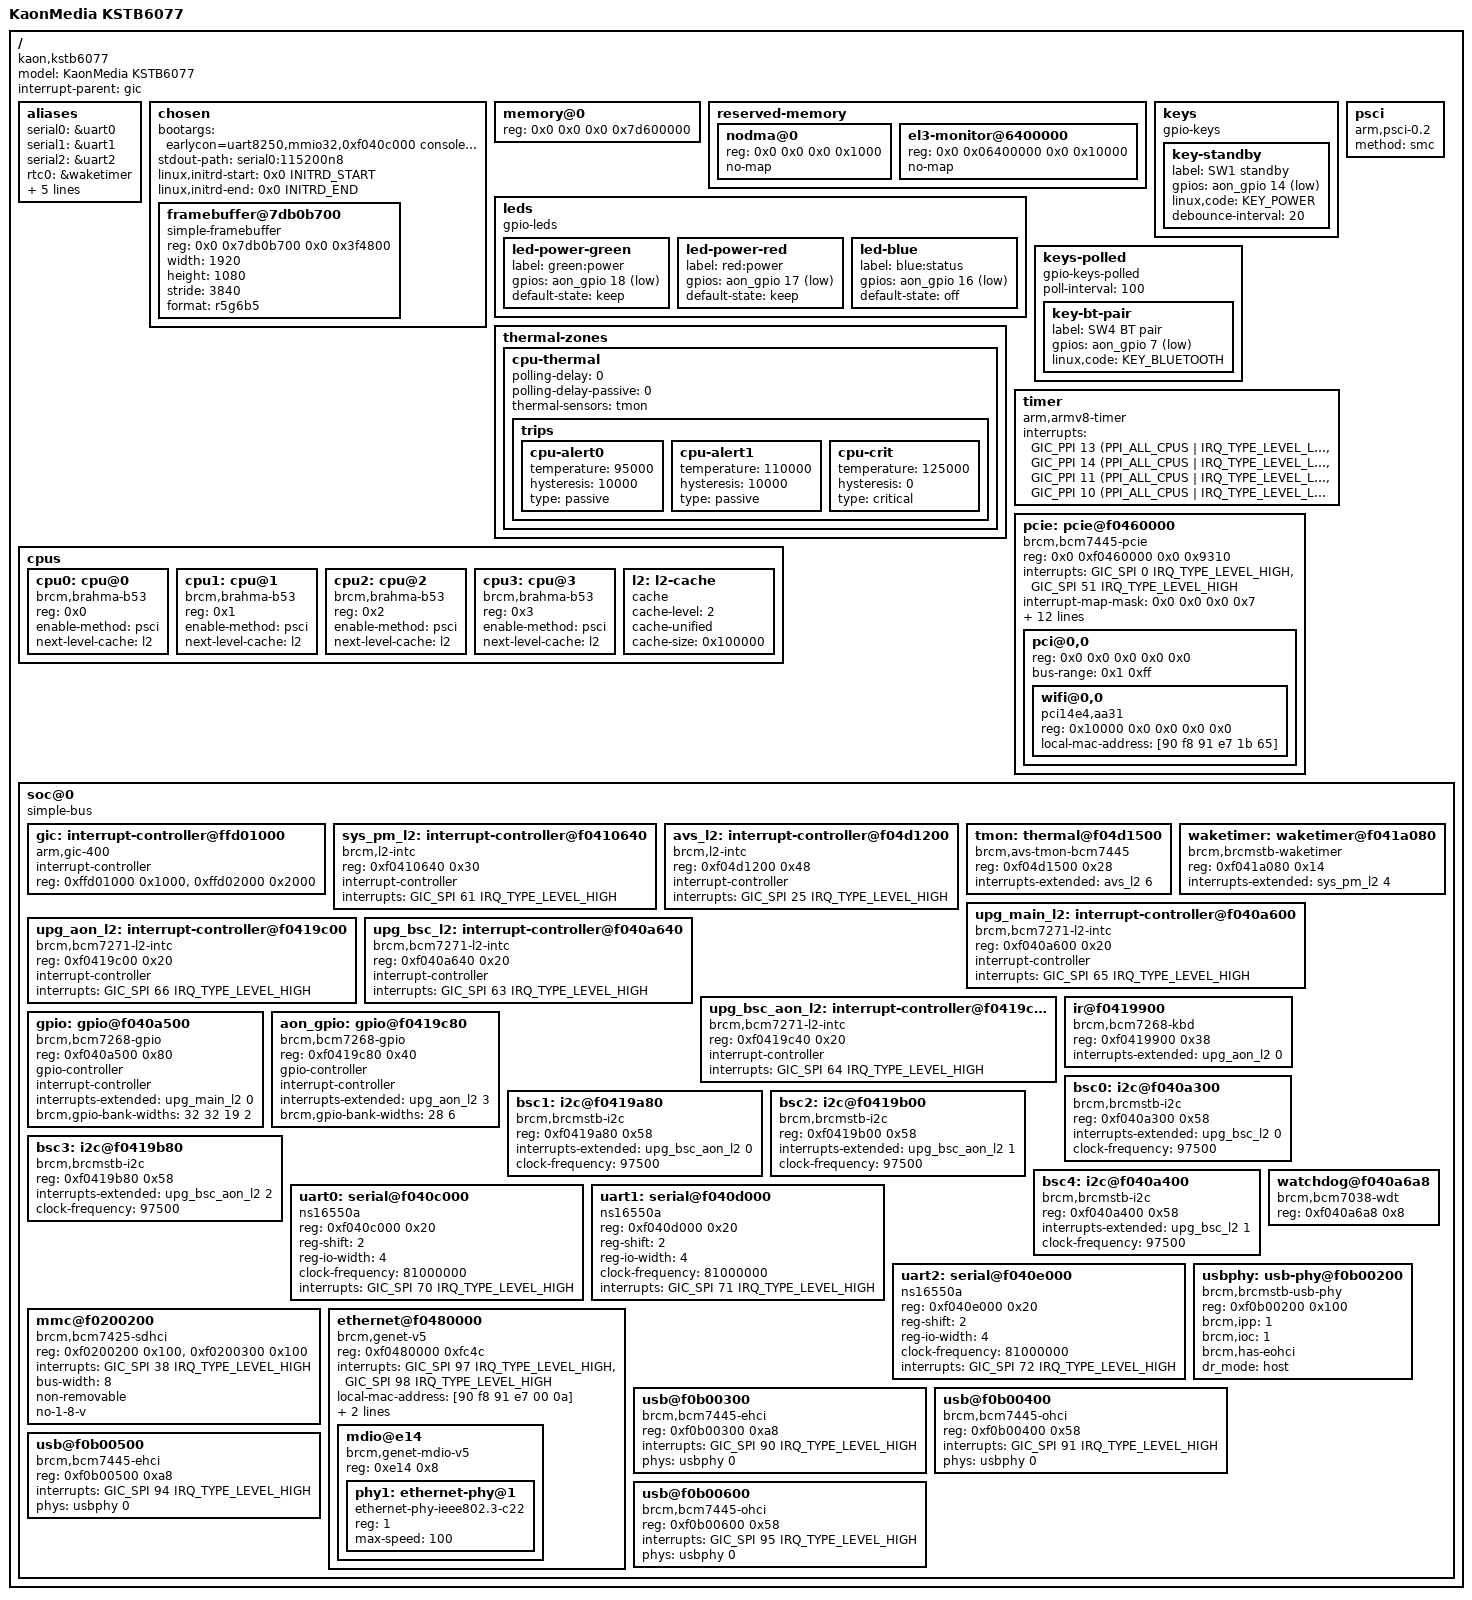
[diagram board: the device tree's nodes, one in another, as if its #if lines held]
// kstb6077.dts - device tree for arm64 Linux on the KSTB6077 (BCM7268 B0).
//
// Written by hand from the tested chapters in docs/ (no BCM7268 tree exists
// upstream). Only what has been checked is described; more nodes are added
// as each driver is tried. INITRD_START/INITRD_END come from the Makefile.

/dts-v1/;

#define GIC_SPI 0
#define GIC_PPI 1
#define IRQ_TYPE_LEVEL_HIGH 4
#define IRQ_TYPE_LEVEL_LOW 8
#define IRQ_TYPE_EDGE_BOTH 3
#define PPI_ALL_CPUS (0xf << 8)
#define GPIO_ACTIVE_LOW 1
#define GPIO_OPEN_DRAIN 6
#define EV_KEY 1
#define KEY_POWER 116
#define KEY_BLUETOOTH 237

/ {
	model = "KaonMedia KSTB6077";
	compatible = "kaon,kstb6077", "brcm,bcm7268";
	#address-cells = <2>;
	#size-cells = <2>;
	interrupt-parent = <&gic>;

	aliases {
		serial0 = &uart0;
		serial1 = &uart1;
		serial2 = &uart2;
		rtc0 = &waketimer;
		i2c0 = &bsc0;
		i2c1 = &bsc1;
		i2c2 = &bsc2;
		i2c3 = &bsc3;
		i2c4 = &bsc4;
	};

	chosen {
		#address-cells = <2>;
		#size-cells = <2>;
		ranges;
		// earlycon without a baud rate: it keeps BOLT's divisor (44, 115200).
		// ROOTFS: root on ROOT (mmcblk0p8), read-only until kstb-rc has checked
		// it with fsck; else the initramfs
#ifdef ROOTFS
		bootargs = "earlycon=uart8250,mmio32,0xf040c000 console=tty0 console=ttyS0,115200 root=/dev/mmcblk0p8 rootfstype=ext4 rootwait ro";
#else
		bootargs = "earlycon=uart8250,mmio32,0xf040c000 console=tty0 console=ttyS0,115200 rdinit=/sbin/init";
#endif
		stdout-path = "serial0:115200n8";
#ifndef ROOTFS
		linux,initrd-start = <0x0 INITRD_START>;
		linux,initrd-end = <0x0 INITRD_END>;
#endif

		// BOLT's splash framebuffer, which kmon keeps on screen at 1080p59.94
		// (docs/hardware/display.md); the display keeps scanning it out
		framebuffer@7db0b700 {
			compatible = "simple-framebuffer";
			reg = <0x0 0x7db0b700 0x0 0x3f4800>;
			width = <1920>;
			height = <1080>;
			stride = <3840>;
			format = "r5g6b5";
		};
	};

	// 2 GB at 0 (docs/hardware/memory-map.md). Linux gets everything below
	// the display and audio buffers at 0x7d600000; above that the display
	// keeps scanning out and the secure regions (BL31, SRR) start at 0x7df00000.
	memory@0 {
		device_type = "memory";
		reg = <0x0 0x0 0x0 0x7d600000>;
	};

	reserved-memory {
		#address-cells = <2>;
		#size-cells = <2>;
		ranges;

		// DTB reserved-nodma
		nodma@0 {
			reg = <0x0 0x0 0x0 0x1000>;
			no-map;
		};

		// kboot's EL3 monitor (or BOLT's smm64): PSCI, cores' EL3 stacks
		el3-monitor@6400000 {
			reg = <0x0 0x06400000 0x0 0x10000>;
			no-map;
		};
	};

	// front LEDs on AON GPIO bank 0 (docs/hardware/gpio.md), open-drain,
	// active-low. BOLT leaves green on; blue is an input until Linux drives it
	leds {
		compatible = "gpio-leds";

		led-power-green {
			label = "green:power";
			gpios = <&aon_gpio 18 (GPIO_ACTIVE_LOW | GPIO_OPEN_DRAIN)>;
			default-state = "keep";
		};

		led-power-red {
			label = "red:power";
			gpios = <&aon_gpio 17 (GPIO_ACTIVE_LOW | GPIO_OPEN_DRAIN)>;
			default-state = "keep";
		};

		led-blue {
			label = "blue:status";
			gpios = <&aon_gpio 16 (GPIO_ACTIVE_LOW | GPIO_OPEN_DRAIN)>;
			default-state = "off";
		};
	};

	// SW1, the front standby button: AON GPIO 14, active-low, interrupt on
	// both edges through the AON L2 (bit 3)
	keys {
		compatible = "gpio-keys";

		key-standby {
			label = "SW1 standby";
			gpios = <&aon_gpio 14 GPIO_ACTIVE_LOW>;
			linux,code = <KEY_POWER>;
			debounce-interval = <20>;
		};
	};

	// SW4, the recovery / Bluetooth-pairing button: AON GPIO 7, active-low;
	// polled, as in the stock DTB
	keys-polled {
		compatible = "gpio-keys-polled";
		poll-interval = <100>;

		key-bt-pair {
			label = "SW4 BT pair";
			gpios = <&aon_gpio 7 GPIO_ACTIVE_LOW>;
			linux,code = <KEY_BLUETOOTH>;
		};
	};

	// AVS temperature monitor; trips as in the stock DTB (95 / 110 / 125 °C,
	// passive, no cooling device yet) plus a critical one, reported by the
	// TMON's interrupt instead of polling
	thermal-zones {
		cpu-thermal {
			polling-delay = <0>;
			polling-delay-passive = <0>;
			thermal-sensors = <&tmon>;

			trips {
				cpu-alert0 {
					temperature = <95000>;
					hysteresis = <10000>;
					type = "passive";
				};

				cpu-alert1 {
					temperature = <110000>;
					hysteresis = <10000>;
					type = "passive";
				};

				cpu-crit {
					temperature = <125000>;
					hysteresis = <0>;
					type = "critical";
				};
			};
		};
	};

	psci {
		compatible = "arm,psci-0.2";
		method = "smc";
	};

	cpus {
		#address-cells = <1>;
		#size-cells = <0>;

		cpu0: cpu@0 {
			device_type = "cpu";
			compatible = "brcm,brahma-b53", "arm,cortex-a53";
			reg = <0x0>;
			enable-method = "psci";
			next-level-cache = <&l2>;
		};

		cpu1: cpu@1 {
			device_type = "cpu";
			compatible = "brcm,brahma-b53", "arm,cortex-a53";
			reg = <0x1>;
			enable-method = "psci";
			next-level-cache = <&l2>;
		};

		cpu2: cpu@2 {
			device_type = "cpu";
			compatible = "brcm,brahma-b53", "arm,cortex-a53";
			reg = <0x2>;
			enable-method = "psci";
			next-level-cache = <&l2>;
		};

		cpu3: cpu@3 {
			device_type = "cpu";
			compatible = "brcm,brahma-b53", "arm,cortex-a53";
			reg = <0x3>;
			enable-method = "psci";
			next-level-cache = <&l2>;
		};

		l2: l2-cache {
			compatible = "cache";
			cache-level = <2>;
			cache-unified;
			cache-size = <0x100000>;
		};
	};

	// IDs 29, 30, 27, 26 (docs/hardware/interrupts.md); CNTFRQ (27 MHz) is
	// set at EL3 by kboot or smm64
	timer {
		compatible = "arm,armv8-timer";
		interrupts = <GIC_PPI 13 (PPI_ALL_CPUS | IRQ_TYPE_LEVEL_LOW)>,
			     <GIC_PPI 14 (PPI_ALL_CPUS | IRQ_TYPE_LEVEL_LOW)>,
			     <GIC_PPI 11 (PPI_ALL_CPUS | IRQ_TYPE_LEVEL_LOW)>,
			     <GIC_PPI 10 (PPI_ALL_CPUS | IRQ_TYPE_LEVEL_LOW)>;
	};

	// PCIe (docs/hardware/peripherals.md): the register layout of the
	// driver's generic STB type (RGR1_SW_INIT_1 +0x9210, MISC_REVISION +0x406c
	// = 0x304). Outbound windows, inbound 2 GB at 0 and the interrupts as in
	// the stock DTB (MSI SPI 51 = ID 83, INTA-INTD SPIs 46-49); one lane, the
	// Wi-Fi chip BCM43570 behind it. The stock DTB's Wi-Fi supplies (AON GPIO
	// 21, 26) are left out: the chip comes up with them as inputs or driven low
	pcie: pcie@f0460000 {
		compatible = "brcm,bcm7445-pcie";
		reg = <0x0 0xf0460000 0x0 0x9310>;
		device_type = "pci";
		#address-cells = <3>;
		#size-cells = <2>;
		#interrupt-cells = <1>;
		interrupts = <GIC_SPI 0 IRQ_TYPE_LEVEL_HIGH>,
			     <GIC_SPI 51 IRQ_TYPE_LEVEL_HIGH>;
		interrupt-names = "pcie", "msi";
		interrupt-map-mask = <0x0 0x0 0x0 0x7>;
		interrupt-map = <0 0 0 1 &gic GIC_SPI 46 IRQ_TYPE_LEVEL_HIGH>,
				<0 0 0 2 &gic GIC_SPI 47 IRQ_TYPE_LEVEL_HIGH>,
				<0 0 0 3 &gic GIC_SPI 48 IRQ_TYPE_LEVEL_HIGH>,
				<0 0 0 4 &gic GIC_SPI 49 IRQ_TYPE_LEVEL_HIGH>;
		msi-controller;
		msi-parent = <&pcie>;
		bus-range = <0x0 0xff>;
		linux,pci-domain = <0>;
		ranges = <0x02000000 0x0 0xc0000000 0x0 0xc0000000 0x0 0x08000000>,
			 <0x02000000 0x0 0xc8000000 0x0 0xc8000000 0x0 0x08000000>,
			 <0x02000000 0x0 0xd0000000 0x0 0xd0000000 0x0 0x08000000>,
			 <0x02000000 0x0 0xd8000000 0x0 0xd8000000 0x0 0x08000000>;
		dma-ranges = <0x43000000 0x0 0x0 0x0 0x0 0x0 0x80000000>;
		brcm,scb-sizes = <0x0 0x80000000>;

		pci@0,0 {
			device_type = "pci";
			reg = <0x0 0x0 0x0 0x0 0x0>;
			bus-range = <0x1 0xff>;
			#address-cells = <3>;
			#size-cells = <2>;
			ranges;

			// the Wi-Fi chip on bus 1 (brcmfmac): the MAC from the stock DTB;
			// its board file is the stock nvm.txt, installed as
			// /lib/firmware/brcm/brcmfmac43570-pcie.kaon,kstb6077.txt
			wifi@0,0 {
				compatible = "pci14e4,aa31", "brcm,bcm4329-fmac";
				reg = <0x10000 0x0 0x0 0x0 0x0>;
				local-mac-address = [90 f8 91 e7 1b 65];
			};
		};
	};

	soc@0 {
		compatible = "simple-bus";
		#address-cells = <1>;
		#size-cells = <1>;
		ranges = <0x0 0x0 0x0 0xffffffff>;

		// GIC-400: distributor and CPU interface
		gic: interrupt-controller@ffd01000 {
			compatible = "arm,gic-400";
			#interrupt-cells = <3>;
			#address-cells = <0>;
			interrupt-controller;
			reg = <0xffd01000 0x1000>,
			      <0xffd02000 0x2000>;
		};

		// edge-type L2 controllers (docs/hardware/interrupts.md): sys_pm
		// (wake-up sources: wake timer bit 4) and AVS (TMON bit 6)
		sys_pm_l2: interrupt-controller@f0410640 {
			compatible = "brcm,l2-intc";
			reg = <0xf0410640 0x30>;
			interrupt-controller;
			#interrupt-cells = <1>;
			interrupts = <GIC_SPI 61 IRQ_TYPE_LEVEL_HIGH>;
		};

		avs_l2: interrupt-controller@f04d1200 {
			compatible = "brcm,l2-intc";
			reg = <0xf04d1200 0x48>;
			interrupt-controller;
			#interrupt-cells = <1>;
			interrupts = <GIC_SPI 25 IRQ_TYPE_LEVEL_HIGH>;
		};

		// temperature (docs/hardware/system-blocks.md): 28 nm constants,
		// m°C = 410040 - code * 487
		tmon: thermal@f04d1500 {
			compatible = "brcm,avs-tmon-bcm7445", "brcm,avs-tmon";
			reg = <0xf04d1500 0x28>;
			interrupts-extended = <&avs_l2 6>;
			interrupt-names = "tmon";
			#thermal-sensor-cells = <0>;
		};

		// wake timer: seconds since power-on at 27 MHz; no battery, so it
		// only keeps the time across warm resets
		waketimer: waketimer@f041a080 {
			compatible = "brcm,brcmstb-waketimer";
			reg = <0xf041a080 0x14>;
			interrupts-extended = <&sys_pm_l2 4>;
			interrupt-names = "timer";
		};

		// level-type L2 interrupt controllers of the UPG blocks
		// (docs/hardware/interrupts.md); BOLT leaves every source masked
		upg_main_l2: interrupt-controller@f040a600 {
			compatible = "brcm,bcm7271-l2-intc";
			reg = <0xf040a600 0x20>;
			interrupt-controller;
			#interrupt-cells = <1>;
			interrupts = <GIC_SPI 65 IRQ_TYPE_LEVEL_HIGH>;
		};

		upg_aon_l2: interrupt-controller@f0419c00 {
			compatible = "brcm,bcm7271-l2-intc";
			reg = <0xf0419c00 0x20>;
			interrupt-controller;
			#interrupt-cells = <1>;
			interrupts = <GIC_SPI 66 IRQ_TYPE_LEVEL_HIGH>;
		};

		upg_bsc_l2: interrupt-controller@f040a640 {
			compatible = "brcm,bcm7271-l2-intc";
			reg = <0xf040a640 0x20>;
			interrupt-controller;
			#interrupt-cells = <1>;
			interrupts = <GIC_SPI 63 IRQ_TYPE_LEVEL_HIGH>;
		};

		upg_bsc_aon_l2: interrupt-controller@f0419c40 {
			compatible = "brcm,bcm7271-l2-intc";
			reg = <0xf0419c40 0x20>;
			interrupt-controller;
			#interrupt-cells = <1>;
			interrupts = <GIC_SPI 64 IRQ_TYPE_LEVEL_HIGH>;
		};

		// IR receiver, channel kbd1 (docs/hardware/ir.md): NEC decoded in
		// hardware, one interrupt per frame on AON L2 bit 0. Our own driver,
		// drivers/kstb-ir.c (no mainline one)
		ir@f0419900 {
			compatible = "brcm,bcm7268-kbd";
			reg = <0xf0419900 0x38>;
			interrupts-extended = <&upg_aon_l2 0>;
		};

		// main GPIO (banks of 32, 32, 19, 2), interrupt through UPG main L2 bit 0
		gpio: gpio@f040a500 {
			compatible = "brcm,bcm7268-gpio", "brcm,brcmstb-gpio";
			reg = <0xf040a500 0x80>;
			gpio-controller;
			#gpio-cells = <2>;
			interrupt-controller;
			#interrupt-cells = <2>;
			interrupts-extended = <&upg_main_l2 0>;
			brcm,gpio-bank-widths = <32 32 19 2>;
		};

		// AON GPIO (banks of 28 and 6), interrupt through UPG AON L2 bit 3
		aon_gpio: gpio@f0419c80 {
			compatible = "brcm,bcm7268-gpio", "brcm,brcmstb-gpio";
			reg = <0xf0419c80 0x40>;
			gpio-controller;
			#gpio-cells = <2>;
			interrupt-controller;
			#interrupt-cells = <2>;
			interrupts-extended = <&upg_aon_l2 3>;
			brcm,gpio-bank-widths = <28 6>;
		};

		// the five BSC (I2C) masters (docs/hardware/i2c.md), 97.5 kHz as BOLT
		// and Nexus set them; L2 bits from Nexus. ch0 is the HDMI DDC (EDID
		// at 0x50), ch3 has the demodulator at 0x67, ch2 is empty; on ch1 and
		// ch4 every transfer times out (not wired, or pins not muxed)
		bsc0: i2c@f040a300 {
			compatible = "brcm,brcmstb-i2c";
			reg = <0xf040a300 0x58>;
			interrupts-extended = <&upg_bsc_l2 0>;
			interrupt-names = "iica";
			clock-frequency = <97500>;
			#address-cells = <1>;
			#size-cells = <0>;
		};

		bsc1: i2c@f0419a80 {
			compatible = "brcm,brcmstb-i2c";
			reg = <0xf0419a80 0x58>;
			interrupts-extended = <&upg_bsc_aon_l2 0>;
			interrupt-names = "iicb";
			clock-frequency = <97500>;
			#address-cells = <1>;
			#size-cells = <0>;
		};

		bsc2: i2c@f0419b00 {
			compatible = "brcm,brcmstb-i2c";
			reg = <0xf0419b00 0x58>;
			interrupts-extended = <&upg_bsc_aon_l2 1>;
			interrupt-names = "iicc";
			clock-frequency = <97500>;
			#address-cells = <1>;
			#size-cells = <0>;
		};

		bsc3: i2c@f0419b80 {
			compatible = "brcm,brcmstb-i2c";
			reg = <0xf0419b80 0x58>;
			interrupts-extended = <&upg_bsc_aon_l2 2>;
			interrupt-names = "iicd";
			clock-frequency = <97500>;
			#address-cells = <1>;
			#size-cells = <0>;
		};

		bsc4: i2c@f040a400 {
			compatible = "brcm,brcmstb-i2c";
			reg = <0xf040a400 0x58>;
			interrupts-extended = <&upg_bsc_l2 1>;
			interrupt-names = "iice";
			clock-frequency = <97500>;
			#address-cells = <1>;
			#size-cells = <0>;
		};

		// UART0: 16550, 32-bit registers, 81 MHz clock (docs/hardware/uart.md), ID 102
		uart0: serial@f040c000 {
			compatible = "ns16550a";
			reg = <0xf040c000 0x20>;
			reg-shift = <2>;
			reg-io-width = <4>;
			clock-frequency = <81000000>;
			interrupts = <GIC_SPI 70 IRQ_TYPE_LEVEL_HIGH>;
		};

		// UART1, UART2: like UART0, clocked, pins unknown (docs/hardware/uart.md),
		// IDs 103, 104
		uart1: serial@f040d000 {
			compatible = "ns16550a";
			reg = <0xf040d000 0x20>;
			reg-shift = <2>;
			reg-io-width = <4>;
			clock-frequency = <81000000>;
			interrupts = <GIC_SPI 71 IRQ_TYPE_LEVEL_HIGH>;
		};

		uart2: serial@f040e000 {
			compatible = "ns16550a";
			reg = <0xf040e000 0x20>;
			reg-shift = <2>;
			reg-io-width = <4>;
			clock-frequency = <81000000>;
			interrupts = <GIC_SPI 72 IRQ_TYPE_LEVEL_HIGH>;
		};

		// watchdog (BCM7038 type, 27 MHz); Linux only starts it when opened
		watchdog@f040a6a8 {
			compatible = "brcm,bcm7038-wdt";
			reg = <0xf040a6a8 0x8>;
		};

		// eMMC: SDHCI 1, host 0xf0200200, cfg 0xf0200300 (docs/hardware/storage.md), ID 70
		mmc@f0200200 {
			compatible = "brcm,bcm7425-sdhci", "brcm,sdhci-brcmstb";
			reg = <0xf0200200 0x100>, <0xf0200300 0x100>;
			reg-names = "host", "cfg";
			interrupts = <GIC_SPI 38 IRQ_TYPE_LEVEL_HIGH>;
			bus-width = <8>;
			non-removable;
			no-1-8-v;
		};

		// GENET 0 and the internal 10/100 PHY at MDIO 1 (docs/hardware/ethernet.md),
		// IDs 129 and 130; the MAC is the one in flash0.macadr
		ethernet@f0480000 {
			compatible = "brcm,genet-v5";
			reg = <0xf0480000 0xfc4c>;
			interrupts = <GIC_SPI 97 IRQ_TYPE_LEVEL_HIGH>,
				     <GIC_SPI 98 IRQ_TYPE_LEVEL_HIGH>;
			local-mac-address = [90 f8 91 e7 00 0a];
			phy-mode = "internal";
			phy-handle = <&phy1>;
			#address-cells = <1>;
			#size-cells = <1>;

			mdio@e14 {
				compatible = "brcm,genet-mdio-v5";
				reg = <0xe14 0x8>;
				#address-cells = <1>;
				#size-cells = <0>;

				phy1: ethernet-phy@1 {
					compatible = "ethernet-phy-ieee802.3-c22";
					reg = <1>;
					max-speed = <100>;
				};
			};
		};
		// USB control/PHY block (Broadcom family 7271A0 in phy-brcm-usb-init.c;
		// ipp/ioc as in the stock tree) and the EHCI/OHCI pairs
		// (docs/hardware/usb.md): 0 = internal Bluetooth, 1 = the USB-A port.
		// xHCI not described yet.
		usbphy: usb-phy@f0b00200 {
			compatible = "brcm,brcmstb-usb-phy";
			reg = <0xf0b00200 0x100>;
			reg-names = "ctrl";
			#phy-cells = <1>;
			brcm,ipp = <1>;
			brcm,ioc = <1>;
			brcm,has-eohci;
			dr_mode = "host";
		};

		usb@f0b00300 {
			compatible = "brcm,bcm7445-ehci";
			reg = <0xf0b00300 0xa8>;
			interrupts = <GIC_SPI 90 IRQ_TYPE_LEVEL_HIGH>;
			phys = <&usbphy 0>;
			phy-names = "usbphy";
		};

		usb@f0b00400 {
			compatible = "brcm,bcm7445-ohci", "generic-ohci";
			reg = <0xf0b00400 0x58>;
			interrupts = <GIC_SPI 91 IRQ_TYPE_LEVEL_HIGH>;
			phys = <&usbphy 0>;
			phy-names = "usb";
		};

		usb@f0b00500 {
			compatible = "brcm,bcm7445-ehci";
			reg = <0xf0b00500 0xa8>;
			interrupts = <GIC_SPI 94 IRQ_TYPE_LEVEL_HIGH>;
			phys = <&usbphy 0>;
			phy-names = "usbphy";
		};

		usb@f0b00600 {
			compatible = "brcm,bcm7445-ohci", "generic-ohci";
			reg = <0xf0b00600 0x58>;
			interrupts = <GIC_SPI 95 IRQ_TYPE_LEVEL_HIGH>;
			phys = <&usbphy 0>;
			phy-names = "usb";
		};
	};
};
